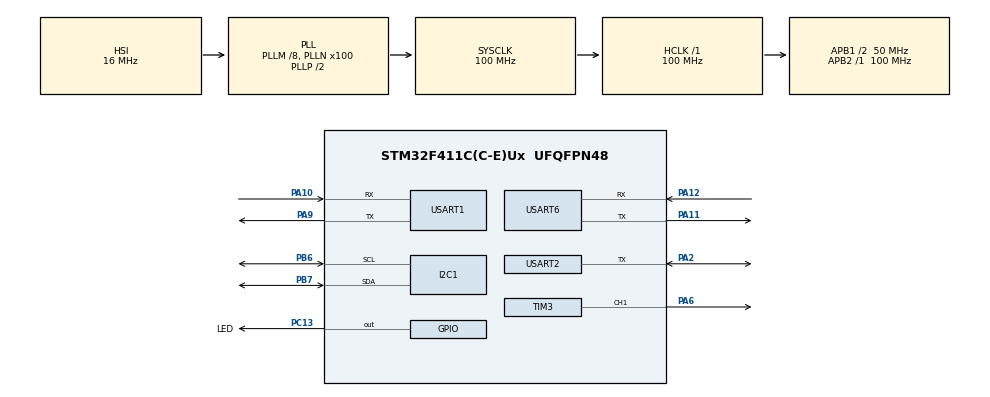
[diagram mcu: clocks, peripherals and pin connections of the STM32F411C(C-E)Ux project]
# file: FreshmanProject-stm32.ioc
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FREERTOS.Tasks01=servoTask,24,512,StartServoTask,As weak,NULL,Dynamic,NULL,NULL;sensorTask,8,512,StartSensorTask,As weak,NULL,Dynamic,NULL,NULL
FREERTOS.configUSE_NEWLIB_REENTRANT=1
Mcu.Family=STM32F4
Mcu.Name=STM32F411C(C-E)Ux
Mcu.Package=UFQFPN48
NVIC.PriorityGroup=NVIC_PRIORITYGROUP_4
NVIC.TIM1_UP_TIM10_IRQn=true\:15\:0\:false\:false\:true\:false\:false\:true\:true
NVIC.TimeBase=TIM1_UP_TIM10_IRQn
NVIC.TimeBaseIP=TIM1
NVIC.USART1_IRQn=true\:5\:0\:false\:false\:true\:true\:true\:true\:true
NVIC.USART6_IRQn=true\:5\:0\:false\:false\:true\:true\:true\:true\:true
PA10.Mode=Asynchronous
PA10.Signal=USART1_RX
PA11.Mode=Asynchronous
PA11.Signal=USART6_TX
PA12.Mode=Asynchronous
PA12.Signal=USART6_RX
PA13.Mode=Serial_Wire
PA13.Signal=SYS_JTMS-SWDIO
PA14.Mode=Serial_Wire
PA14.Signal=SYS_JTCK-SWCLK
PA2.Mode=Half_duplex(single_wire_mode)
PA2.Signal=USART2_TX
PA6.Signal=S_TIM3_CH1
PA9.Mode=Asynchronous
PA9.Signal=USART1_TX
PB6.Mode=I2C
PB6.Signal=I2C1_SCL
PB7.Mode=I2C
PB7.Signal=I2C1_SDA
PC13-ANTI_TAMP.GPIO_Label=LED
PC13-ANTI_TAMP.Signal=GPIO_Output
PC14-OSC32_IN.Mode=LSE-External-Clock-Source
PC14-OSC32_IN.Signal=RCC_OSC32_IN
PC15-OSC32_OUT.Mode=LSE-External-Clock-Source
PC15-OSC32_OUT.Signal=RCC_OSC32_OUT
PH0\ -\ OSC_IN.Mode=HSE-External-Oscillator
PH0\ -\ OSC_IN.Signal=RCC_OSC_IN
PH1\ -\ OSC_OUT.Mode=HSE-External-Oscillator
PH1\ -\ OSC_OUT.Signal=RCC_OSC_OUT
ProjectManager.HeapSize=0x200
ProjectManager.StackSize=0x400
ProjectManager.TargetToolchain=STM32CubeIDE
RCC.48MHZClocksFreq_Value=50000000
RCC.AHBFreq_Value=100000000
RCC.APB1CLKDivider=RCC_HCLK_DIV2
RCC.APB1Freq_Value=50000000
RCC.APB1TimFreq_Value=100000000
RCC.APB2Freq_Value=100000000
RCC.APB2TimFreq_Value=100000000
RCC.CortexFreq_Value=100000000
RCC.HCLKFreq_Value=100000000
RCC.HSE_VALUE=25000000
RCC.HSI_VALUE=16000000
RCC.LSE_VALUE=32768
RCC.PLLM=8
RCC.PLLN=100
RCC.SYSCLKFreq_VALUE=100000000
RCC.SYSCLKSource=RCC_SYSCLKSOURCE_PLLCLK
RCC.VCOOutputFreq_Value=200000000
SH.S_TIM3_CH1.0=TIM3_CH1,PWM Generation1 CH1
STMicroelectronics.X-CUBE-ALGOBUILD.1.3.0.LibraryCcDSPOoLibraryJjDSPOoLibrary=true
TIM3.AutoReloadPreload=TIM_AUTORELOAD_PRELOAD_ENABLE
TIM3.Channel-PWM\ Generation1\ CH1=TIM_CHANNEL_1
TIM3.Period=1000-1
TIM3.Prescaler=2000-1
USART1.VirtualMode=VM_ASYNC
USART2.VirtualMode=VM_ASYNC
USART6.VirtualMode=VM_ASYNC
VP_FREERTOS_VS_CMSIS_V2.Mode=CMSIS_V2
VP_STMicroelectronics.X-CUBE-ALGOBUILD_VS_DSPOoLibraryJjLibrary_1.3.0_1.3.0.Mode=DSPOoLibraryJjLibrary
VP_SYS_VS_tim1.Mode=TIM1
VP_TIM3_VS_ClockSourceINT.Mode=Internal
board=custom

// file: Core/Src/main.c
/* USER CODE BEGIN Header */
/**
  ******************************************************************************
  * @file           : main.c
  * @brief          : Main program body
  ******************************************************************************
  * @attention
  *
  * Copyright (c) 2023 STMicroelectronics.
  * All rights reserved.
  *
  * This software is licensed under terms that can be found in the LICENSE file
  * in the root directory of this software component.
  * If no LICENSE file comes with this software, it is provided AS-IS.
  *
  ******************************************************************************
  */
/* USER CODE END Header */
#include "main.h"
#include "cmsis_os.h"
#include "i2c.h"
#include "tim.h"
#include "usart.h"
#include "gpio.h"

/* USER CODE BEGIN Includes */
#include "retarget.h"
/* USER CODE END Includes */

void SystemClock_Config(void);
void MX_FREERTOS_Init(void);

int main(void)
{

  /* MCU Configuration--------------------------------------------------------*/

  /* Reset of all peripherals, Initializes the Flash interface and the Systick. */
  HAL_Init();

  /* Configure the system clock */
  SystemClock_Config();

  /* Initialize all configured peripherals */
  MX_GPIO_Init();
  MX_I2C1_Init();
  MX_USART1_UART_Init();
  MX_USART2_UART_Init();
  MX_TIM3_Init();
  MX_USART6_UART_Init();
  /* USER CODE BEGIN 2 */
  RetargetInit(&huart1);
  HAL_TIM_PWM_Start(&htim3,TIM_CHANNEL_1);
  __HAL_TIM_SET_COMPARE(&htim3,TIM_CHANNEL_1,125);

  /* USER CODE END 2 */

  /* Init scheduler */
  osKernelInitialize();  /* Call init function for freertos objects (in freertos.c) */
  MX_FREERTOS_Init();

  /* Start scheduler */
  osKernelStart();

  /* We should never get here as control is now taken by the scheduler */
  /* Infinite loop */
  while (1)
  {

  }
}

void SystemClock_Config(void)
{
  RCC_OscInitTypeDef RCC_OscInitStruct = {0};
  RCC_ClkInitTypeDef RCC_ClkInitStruct = {0};

  /** Configure the main internal regulator output voltage
  */
  __HAL_RCC_PWR_CLK_ENABLE();
  __HAL_PWR_VOLTAGESCALING_CONFIG(PWR_REGULATOR_VOLTAGE_SCALE1);

  /** Initializes the RCC Oscillators according to the specified parameters
  * in the RCC_OscInitTypeDef structure.
  */
  RCC_OscInitStruct.OscillatorType = RCC_OSCILLATORTYPE_HSI;
  RCC_OscInitStruct.HSIState = RCC_HSI_ON;
  RCC_OscInitStruct.HSICalibrationValue = RCC_HSICALIBRATION_DEFAULT;
  RCC_OscInitStruct.PLL.PLLState = RCC_PLL_ON;
  RCC_OscInitStruct.PLL.PLLSource = RCC_PLLSOURCE_HSI;
  RCC_OscInitStruct.PLL.PLLM = 8;
  RCC_OscInitStruct.PLL.PLLN = 100;
  RCC_OscInitStruct.PLL.PLLP = RCC_PLLP_DIV2;
  RCC_OscInitStruct.PLL.PLLQ = 4;
  if (HAL_RCC_OscConfig(&RCC_OscInitStruct) != HAL_OK)
  {
    Error_Handler();
  }

  /** Initializes the CPU, AHB and APB buses clocks
  */
  RCC_ClkInitStruct.ClockType = RCC_CLOCKTYPE_HCLK|RCC_CLOCKTYPE_SYSCLK
                              |RCC_CLOCKTYPE_PCLK1|RCC_CLOCKTYPE_PCLK2;
  RCC_ClkInitStruct.SYSCLKSource = RCC_SYSCLKSOURCE_PLLCLK;
  RCC_ClkInitStruct.AHBCLKDivider = RCC_SYSCLK_DIV1;
  RCC_ClkInitStruct.APB1CLKDivider = RCC_HCLK_DIV2;
  RCC_ClkInitStruct.APB2CLKDivider = RCC_HCLK_DIV1;

  if (HAL_RCC_ClockConfig(&RCC_ClkInitStruct, FLASH_LATENCY_3) != HAL_OK)
  {
    Error_Handler();
  }
}

void HAL_TIM_PeriodElapsedCallback(TIM_HandleTypeDef *htim)
{
  if (htim->Instance == TIM1) {
    HAL_IncTick();
  }
}

void Error_Handler(void)
{
  __disable_irq();
  while (1)
  {
  }
}

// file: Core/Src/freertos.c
/* USER CODE BEGIN Header */
/**
  ******************************************************************************
  * File Name          : freertos.c
  * Description        : Code for freertos applications
  ******************************************************************************
  * @attention
  *
  * Copyright (c) 2023 STMicroelectronics.
  * All rights reserved.
  *
  * This software is licensed under terms that can be found in the LICENSE file
  * in the root directory of this software component.
  * If no LICENSE file comes with this software, it is provided AS-IS.
  *
  ******************************************************************************
  */
/* USER CODE END Header */

#include "FreeRTOS.h"
#include "task.h"
#include "main.h"
#include "cmsis_os.h"

/* USER CODE BEGIN Includes */
#include "semphr.h"
/* USER CODE END Includes */

/* USER CODE BEGIN Variables */
SemaphoreHandle_t data_mutex;
SemaphoreHandle_t sync_mutex;
/* USER CODE END Variables */
/* Definitions for servoTask */
osThreadId_t servoTaskHandle;
const osThreadAttr_t servoTask_attributes = {
  .name = "servoTask",
  .stack_size = 512 * 4,
  .priority = (osPriority_t) osPriorityNormal,
};
/* Definitions for sensorTask */
osThreadId_t sensorTaskHandle;
const osThreadAttr_t sensorTask_attributes = {
  .name = "sensorTask",
  .stack_size = 512 * 4,
  .priority = (osPriority_t) osPriorityLow,
};

void StartServoTask(void *argument);
void StartSensorTask(void *argument);

void MX_FREERTOS_Init(void); /* (MISRA C 2004 rule 8.1) */

void MX_FREERTOS_Init(void) {

  /* USER CODE BEGIN RTOS_SEMAPHORES */
  /* add semaphores, ... */
    data_mutex = xSemaphoreCreateMutex();
    sync_mutex = xSemaphoreCreateMutex();
  /* USER CODE END RTOS_SEMAPHORES */

  /* Create the thread(s) */
  /* creation of servoTask */
  //servoTaskHandle = osThreadNew(StartServoTask, NULL, &servoTask_attributes);

  /* creation of sensorTask */
  sensorTaskHandle = osThreadNew(StartSensorTask, NULL, &sensorTask_attributes);

}

__weak void StartServoTask(void *argument)
{
  for(;;)
  {
    osDelay(1);
  }
}

__weak void StartSensorTask(void *argument)
{
  for(;;)
  {
    osDelay(1);
  }
}
